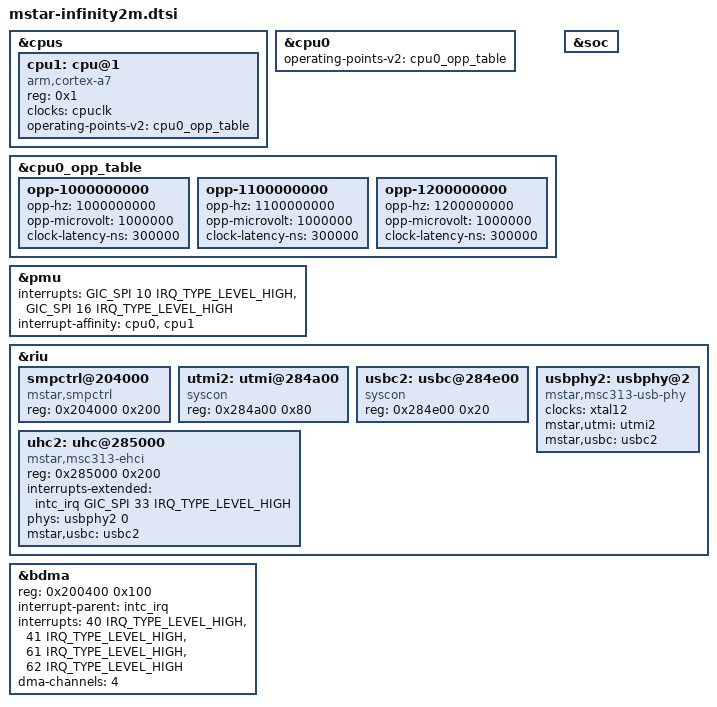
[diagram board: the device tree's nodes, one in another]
// SPDX-License-Identifier: GPL-2.0
/*
 * Copyright (c) 2020 thingy.jp.
 * Author: Daniel Palmer <daniel@thingy.jp>
 */

#include "mstar-infinity.dtsi"

/ {
};

&cpus {
	cpu1: cpu@1 {
		device_type = "cpu";
		compatible = "arm,cortex-a7";
		reg = <0x1>;
		clocks = <&cpuclk>;
		clock-names = "cpuclk";
		operating-points-v2 = <&cpu0_opp_table>;
	};
};

&cpu0 {
	operating-points-v2 = <&cpu0_opp_table>;
};

&cpu0_opp_table {
	opp-1000000000 {
		opp-hz = /bits/ 64 <1000000000>;
		opp-microvolt = <1000000>;
		clock-latency-ns = <300000>;
	};

	opp-1100000000 {
		opp-hz = /bits/ 64 <1100000000>;
		opp-microvolt = <1000000>;
		clock-latency-ns = <300000>;
	};

	opp-1200000000 {
		opp-hz = /bits/ 64 <1200000000>;
		opp-microvolt = <1000000>;
		clock-latency-ns = <300000>;
	};
};

&pmu {
		interrupts = <GIC_SPI 10 IRQ_TYPE_LEVEL_HIGH>,
			     <GIC_SPI 16 IRQ_TYPE_LEVEL_HIGH>;
		interrupt-affinity = <&cpu0>, <&cpu1>;
};

&soc {
	//start address for second cpu
	//0x1F20404C
	//0x1F204050
	//0x1F204058 -- unlock
};

&riu {
	smpctrl@204000 {
		compatible = "mstar,smpctrl";
		reg = <0x204000 0x200>;
		status = "okay";
	};

	utmi2: utmi@284a00 {
		compatible = "syscon";
		reg = <0x284a00 0x80>;
	};

	usbc2: usbc@284e00 {
		compatible = "syscon";
		reg = <0x284e00 0x20>;
	};

	usbphy2: usbphy@2 {
		#phy-cells = <1>;
		compatible = "mstar,msc313-usb-phy";
		clocks = <&xtal12>;
		mstar,utmi = <&utmi2>;
		mstar,usbc = <&usbc2>;
		//status = "disabled";
	};

	uhc2: uhc@285000 {
		compatible = "mstar,msc313-ehci";
		reg = <0x285000 0x200>;
		interrupts-extended = <&intc_irq GIC_SPI 33 IRQ_TYPE_LEVEL_HIGH>;
		phys = <&usbphy2 0>;
		phy-names = "usb";
		mstar,usbc = <&usbc2>;
		//status = "disabled";
	};
};

&bdma {
	reg = <0x200400 0x100>;
	interrupt-parent = <&intc_irq>;
	interrupts = <40 IRQ_TYPE_LEVEL_HIGH>,
		     <41 IRQ_TYPE_LEVEL_HIGH>,
		     <61 IRQ_TYPE_LEVEL_HIGH>,
		     <62 IRQ_TYPE_LEVEL_HIGH>;
	dma-channels = <4>;
};
